# nrf5340_application register map
Vendor: Nordic Semiconductor; Series: nrf53; File version: 1
CPU: CM33 r0p4, little endian, MPU, FPU, 3 interrupt priority bits, 69 interrupts
Registers are 32-bit, read-write, reset 0x0 unless marked. A register's access mark holds for its fields unless they carry their own. Offsets are from the block's base; [hi:lo] are bit positions; lines under a group give offsets from that group; {n}, {i} and the like mark numbered series; 'fields as' and 'values as' point back to an identical list.

## OSCILLATORS_NS — Oscillator control 0
Base 0x40004000
Same registers: OSCILLATORS_S 0x50004000
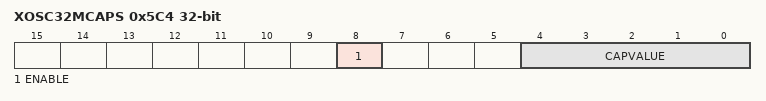
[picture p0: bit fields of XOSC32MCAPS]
0x5C4 XOSC32MCAPS — Programmable capacitance of XC1 and XC2
  [8] ENABLE — Enable on-chip capacitors on XC1 and XC2
    0=Disabled (Capacitor disabled (use external caps)); 1=Enabled (Capacitor enabled)
  [4:0] CAPVALUE — Value representing capacitance, calculated using provided equation
0x6C0 XOSC32KI group — Unspecified
  0x00 BYPASS — Enable or disable bypass of LFCLK crystal oscillator with external clock source
    [0] BYPASS
      0=Disabled (Disable (use with crystal or low-swing external source)); 1=Enabled (Enable (use with rail-to-rail external source))
  0x10 INTCAP — Control usage of internal load capacitors
    [1:0] INTCAP
      0=External (Use external load capacitors); 1=C6PF (6 pF internal load capacitance); 2=C7PF (7 pF internal load capacitance); 3=C9PF (9 pF internal load capacitance)

## REGULATORS_NS — Voltage regulators 0
Base 0x40004000; alternate view of OSCILLATORS_NS
Same registers: REGULATORS_S 0x50004000 (alternate view of OSCILLATORS_S)
0x428 MAINREGSTATUS ro — Main supply status
  [0] VREGH — VREGH status
    0=Inactive (Normal voltage mode. Voltage supplied on VDD and VDDH.); 1=Active (High voltage mode. Voltage supplied on VDDH.)
0x500 SYSTEMOFF wo
  [0] SYSTEMOFF — Enable System OFF mode
    1=Enter (Enable System OFF mode)
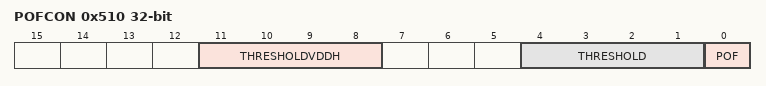
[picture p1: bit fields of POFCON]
0x510 POFCON — Power-fail comparator configuration
  [11:8] THRESHOLDVDDH — Power-fail comparator threshold setting for voltage supply on VDDH
    0=V27 (Set threshold to 2.7 V); 1=V28 (Set threshold to 2.8 V); 2=V29 (Set threshold to 2.9 V); 3=V30 (Set threshold to 3.0 V); 4=V31 (Set threshold to 3.1 V); 5=V32 (Set threshold to 3.2 V); 6=V33 (Set threshold to 3.3 V); 7=V34 (Set threshold to 3.4 V); 8=V35 (Set threshold to 3.5 V); 9=V36 (Set threshold to 3.6 V); 10=V37 (Set threshold to 3.7 V); 11=V38 (Set threshold to 3.8 V); 12=V39 (Set threshold to 3.9 V); 13=V40 (Set threshold to 4.0 V); 14=V41 (Set threshold to 4.1 V); 15=V42 (Set threshold to 4.2 V)
  [4:1] THRESHOLD — Power-fail comparator threshold setting
    6=V19 (Set threshold to 1.9 V); 7=V20 (Set threshold to 2.0 V); 8=V21 (Set threshold to 2.1 V); 9=V22 (Set threshold to 2.2 V); 10=V23 (Set threshold to 2.3 V); 11=V24 (Set threshold to 2.4 V); 12=V25 (Set threshold to 2.5 V); 13=V26 (Set threshold to 2.6 V); 14=V27 (Set threshold to 2.7 V); 15=V28 (Set threshold to 2.8 V)
  [0] POF — Enable or disable power-fail comparator
    0=Disabled; 1=Enabled
0x704 VREGMAIN group — Unspecified
  0x00 DCDCEN — DC/DC enable register for VREGMAIN
    [0] DCDCEN — Enable or disable DC/DC converter
      0=Disabled; 1=Enabled
0x900 VREGRADIO group — Unspecified
  0x04 DCDCEN — DC/DC enable register for VREGRADIO
    fields as VREGMAIN.DCDCEN
0xB00 VREGH group — Unspecified
  0x00 DCDCEN — DC/DC enable register for VREGH
    fields as VREGMAIN.DCDCEN
  0x40 EXTSILENTEN reset 0x1 — When VREGH is in DC/DC mode, enable VREGH silent mode to supply external components from VDD. Silent mode has lower voltage ripple. Silent mode is used when DC/DC is enabled, and is ignored in LDO mode. Disabling silent mode reduces current consumption in sleep.
    [0] EXTSILENTEN — Enable silent external DC/DC supply
      0=Disabled; 1=Enabled

## POWER_NS — Power control 0
Base 0x40005000; alternate view of CLOCK_NS
Same registers: POWER_S 0x50005000 (alternate view of CLOCK_S)
0x78 TASKS_CONSTLAT wo — Enable Constant Latency mode
  [0] TASKS_CONSTLAT
    1=Trigger task
0x7C TASKS_LOWPWR wo — Enable Low-Power mode (variable latency)
  [0] TASKS_LOWPWR
    1=Trigger task
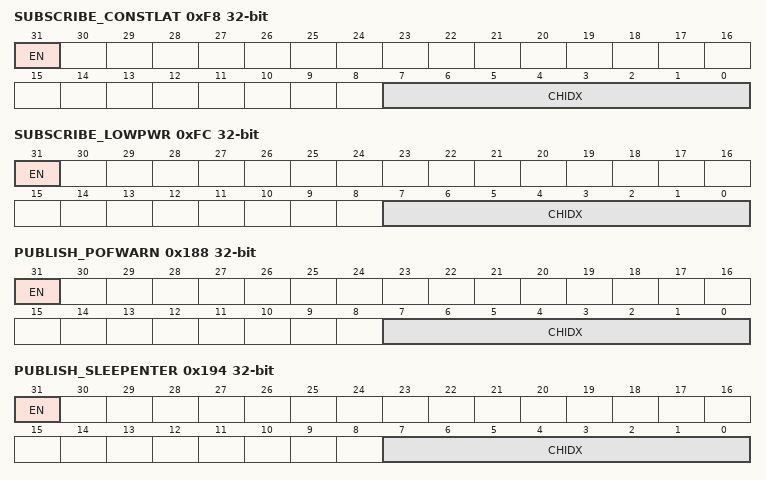
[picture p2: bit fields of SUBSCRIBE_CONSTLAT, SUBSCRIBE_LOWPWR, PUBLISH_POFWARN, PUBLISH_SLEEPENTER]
0xF8 SUBSCRIBE_CONSTLAT — Subscribe configuration for task CONSTLAT
  [31] EN
    0=Disabled (Disable subscription); 1=Enabled (Enable subscription)
  [7:0] CHIDX — DPPI channel that task CONSTLAT will subscribe to
0xFC SUBSCRIBE_LOWPWR — Subscribe configuration for task LOWPWR
  [31] EN
    values as SUBSCRIBE_CONSTLAT.EN
  [7:0] CHIDX — DPPI channel that task LOWPWR will subscribe to
0x108 EVENTS_POFWARN — Power failure warning
  [0] EVENTS_POFWARN
    0=NotGenerated (Event not generated); 1=Generated (Event generated)
0x114 EVENTS_SLEEPENTER — CPU entered WFI/WFE sleep
  [0] EVENTS_SLEEPENTER
    values as EVENTS_POFWARN.EVENTS_POFWARN
0x118 EVENTS_SLEEPEXIT — CPU exited WFI/WFE sleep
  [0] EVENTS_SLEEPEXIT
    values as EVENTS_POFWARN.EVENTS_POFWARN
0x188 PUBLISH_POFWARN — Publish configuration for event POFWARN
  [31] EN
    0=Disabled (Disable publishing); 1=Enabled (Enable publishing)
  [7:0] CHIDX — DPPI channel that event POFWARN will publish to
0x194 PUBLISH_SLEEPENTER — Publish configuration for event SLEEPENTER
  [31] EN
    values as PUBLISH_POFWARN.EN
  [7:0] CHIDX — DPPI channel that event SLEEPENTER will publish to
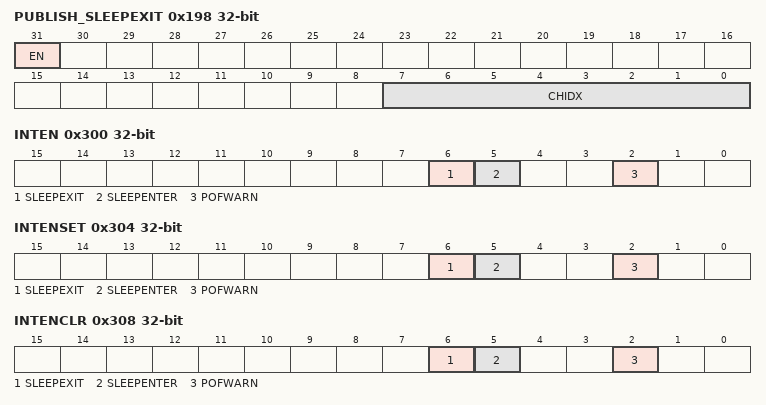
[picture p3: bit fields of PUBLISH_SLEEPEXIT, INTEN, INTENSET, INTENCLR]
0x198 PUBLISH_SLEEPEXIT — Publish configuration for event SLEEPEXIT
  [31] EN
    values as PUBLISH_POFWARN.EN
  [7:0] CHIDX — DPPI channel that event SLEEPEXIT will publish to
0x300 INTEN — Enable or disable interrupt
  [all] fields
    0=Disabled; 1=Enabled
  [6] SLEEPEXIT — Enable or disable interrupt for event SLEEPEXIT
  [5] SLEEPENTER — Enable or disable interrupt for event SLEEPENTER
  [2] POFWARN — Enable or disable interrupt for event POFWARN
0x304 INTENSET — Enable interrupt
  [all] fields
    on read: 0=Disabled (Read: Disabled); 1=Enabled (Read: Enabled) | on write: 1=Set (Enable)
  [6] SLEEPEXIT — Write '1' to enable interrupt for event SLEEPEXIT
  [5] SLEEPENTER — Write '1' to enable interrupt for event SLEEPENTER
  [2] POFWARN — Write '1' to enable interrupt for event POFWARN
0x308 INTENCLR — Disable interrupt
  [all] fields
    on read: 0=Disabled (Read: Disabled); 1=Enabled (Read: Enabled) | on write: 1=Clear (Disable)
  [6] SLEEPEXIT — Write '1' to disable interrupt for event SLEEPEXIT
  [5] SLEEPENTER — Write '1' to disable interrupt for event SLEEPENTER
  [2] POFWARN — Write '1' to disable interrupt for event POFWARN
{0x51C+4i} GPREGRET[{i}] (i=0..1) — Description collection: General purpose retention register
  [7:0] GPREGRET — General purpose retention register
